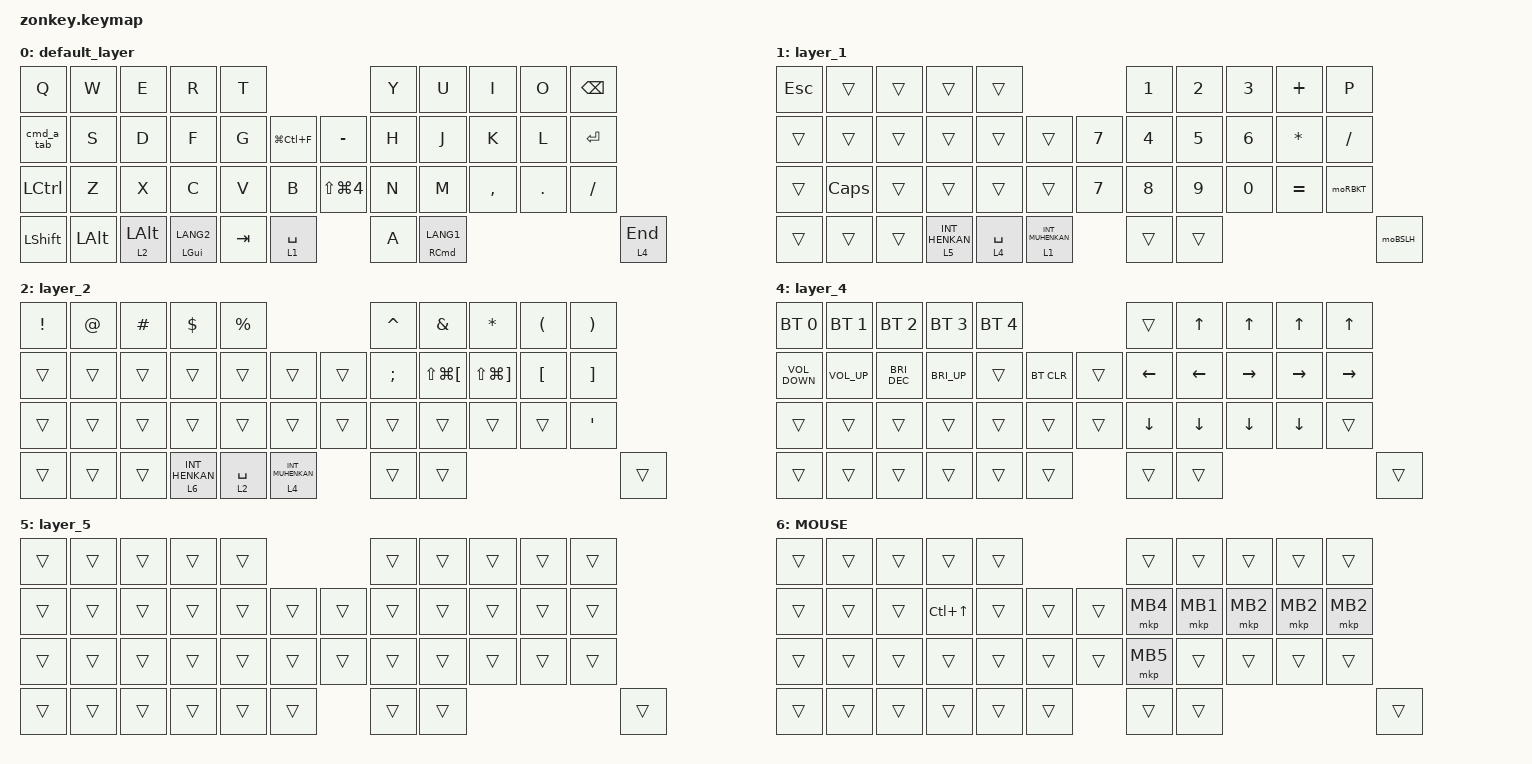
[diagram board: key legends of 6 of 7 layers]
#include <behaviors.dtsi>
#include <dt-bindings/zmk/bt.h>
#include <dt-bindings/zmk/keys.h>
#include <dt-bindings/zmk/pointing.h>

#define ZMK_POINTING_DEFAULT_SCRL_VAL 100
#define JIS 1
#define BT 4
#define MOUSE 6

&mt {
    flavor = "balanced";
    quick-tap-ms = <0>;
};

/ {
    behaviors {
        cmd_a_tab: cmd_a_tab {
            compatible = "zmk,behavior-mod-morph";
            #binding-cells = <0>;

            /* Tab 単体を送る */

            bindings = <&kp A>, <&kp TAB>;

            /* Left GUI が押されている時だけモーフ */

            mods = <(MOD_LGUI)>;

            /* その Left GUI をホストへ“保持”して渡す！ */

            keep-mods = <(MOD_LGUI)>;
        };

        cmd_sel_all: cmd_sel_all {
            compatible = "zmk,behavior-macro";
            #binding-cells = <0>;
            bindings = <&kp LEFT_GUI &kp A>;   /* ⌘ と A を同時送信 */
            label = "CMD_SELECT_ALL";
        };
    };

    macros {
        to_layer_0: to_layer_0 {
            compatible = "zmk,behavior-macro-one-param";
            #binding-cells = <1>;
            bindings = <&to 0 &macro_param_1to1 &kp MACRO_PLACEHOLDER>;
            label = "TO_LAYER_0";
        };

        screenshot_select: screenshot_select {
            compatible = "zmk,behavior-macro";
            #binding-cells = <0>;
            bindings = <&kp LEFT_GUI &kp LEFT_SHIFT &kp KP_NUMBER_4>;
            label = "SCREENSHOT_SELECT";
        };
    };

    behaviors {
        lt_to_layer_0: lt_to_layer_0 {
            compatible = "zmk,behavior-hold-tap";
            label = "LAYER_TAP_TO_0";
            bindings = <&mo>, <&to_layer_0>;

            #binding-cells = <2>;
            tapping-term-ms = <10>;
        };

        toJIS: toJIS {
            compatible = "zmk,behavior-hold-tap";
            label = "toJIS";
            #binding-cells = <2>;
            tapping-term-ms = <200>;
            quick-tap-ms = <0>;
            bindings = <&tog>, <&kp>;
        };

        mo2: mo2 {
            compatible = "zmk,behavior-mod-morph";
            #binding-cells = <0>;
            bindings = <&kp N2>, <&kp DQT>;

            mods = <(MOD_LSFT|MOD_RSFT)>;
        };

        mo6: mo6 {
            compatible = "zmk,behavior-mod-morph";
            #binding-cells = <0>;
            bindings = <&kp N6>, <&kp AMPS>;

            mods = <(MOD_LSFT|MOD_RSFT)>;
        };

        mo7: mo7 {
            compatible = "zmk,behavior-mod-morph";
            #binding-cells = <0>;
            bindings = <&kp N7>, <&kp APOS>;

            mods = <(MOD_LSFT|MOD_RSFT)>;
        };

        mo8: mo8 {
            compatible = "zmk,behavior-mod-morph";
            #binding-cells = <0>;
            bindings = <&kp N8>, <&kp LPAR>;

            mods = <(MOD_LSFT|MOD_RSFT)>;
        };

        mo9: mo9 {
            compatible = "zmk,behavior-mod-morph";
            #binding-cells = <0>;
            bindings = <&kp N9>, <&kp RPAR>;

            mods = <(MOD_LSFT|MOD_RSFT)>;
        };

        moMINUS: moMINUS {
            compatible = "zmk,behavior-mod-morph";
            #binding-cells = <0>;
            bindings = <&kp MINUS>, <&kp EQUAL>;

            mods = <(MOD_LSFT|MOD_RSFT)>;
        };

        moCARET: moCARET {
            compatible = "zmk,behavior-mod-morph";
            #binding-cells = <0>;
            bindings = <&kp CARET>, <&kp TILDE>;

            mods = <(MOD_LSFT|MOD_RSFT)>;
        };

        moINT3: moINT3 {
            compatible = "zmk,behavior-mod-morph";
            #binding-cells = <0>;
            bindings = <&kp INT3>, <&kp PIPE>;

            mods = <(MOD_LSFT|MOD_RSFT)>;
        };

        moAT: moAT {
            compatible = "zmk,behavior-mod-morph";
            #binding-cells = <0>;
            bindings = <&kp AT>, <&kp GRAVE>;

            mods = <(MOD_LSFT|MOD_RSFT)>;
        };

        moLBKT: moLBKT {
            compatible = "zmk,behavior-mod-morph";
            #binding-cells = <0>;
            bindings = <&kp LBKT>, <&kp LS(LBRC)>;

            mods = <(MOD_LSFT|MOD_RSFT)>;
        };

        moRBKT: moRBKT {
            compatible = "zmk,behavior-mod-morph";
            #binding-cells = <0>;
            bindings = <&kp RBKT>, <&kp LS(RBRC)>;

            mods = <(MOD_LSFT|MOD_RSFT)>;
        };

        moSEMI: moSEMI {
            compatible = "zmk,behavior-mod-morph";
            #binding-cells = <0>;
            bindings = <&kp SEMI>, <&kp PLUS>;

            mods = <(MOD_LSFT|MOD_RSFT)>;
        };

        moCOLON: moCOLON {
            compatible = "zmk,behavior-mod-morph";
            #binding-cells = <0>;
            bindings = <&kp COLON>, <&kp ASTRK>;

            mods = <(MOD_LSFT|MOD_RSFT)>;
        };

        moBSLH: moBSLH {
            compatible = "zmk,behavior-mod-morph";
            #binding-cells = <0>;
            bindings = <&kp BSLH>, <&kp UNDER>;

            mods = <(MOD_LSFT|MOD_RSFT)>;
        };

        /* New behaviour: Cmd+A → Cmd+Tab, A 単押し → a */

        a_cmd_tab: a_cmd_tab {
            compatible = "zmk,behavior-mod-morph";
            #binding-cells = <0>;
            bindings = <&kp A>, <&kp TAB>;

            mods = <(MOD_LGUI)>;
        };

        scroll_down_up: behavior_sensor_rotate_mouse_wheel_down_up {
            compatible = "zmk,behavior-sensor-rotate";
            #sensor-binding-cells = <0>;
            bindings = <&msc SCRL_DOWN>, <&msc SCRL_UP>;

            tap-ms = <20>;
        };
    };

    keymap {
        compatible = "zmk,keymap";

        default_layer {
            bindings = <
&kp Q             &kp W         &kp E           &kp R               &kp T                                           &kp Y  &kp U                    &kp I      &kp O       &kp BACKSPACE
&cmd_a_tab        &kp S         &kp D           &kp F               &kp G    &kp LG(LC(F))    &kp MINUS             &kp H  &kp J                    &kp K      &kp L       &kp ENTER
&kp LEFT_CONTROL  &kp Z         &kp X           &kp C               &kp V    &kp B            &kp LS(LG(NUMBER_4))  &kp N  &kp M                    &kp COMMA  &kp PERIOD  &kp SLASH
&kp LEFT_SHIFT    &kp LEFT_ALT  &lt 2 LEFT_ALT  &mt LEFT_GUI LANG2  &kp TAB  &lt 1 SPACE                            &kp A  &mt RIGHT_COMMAND LANG1                                        &lt 4 END
            >;

            sensor-bindings =
                <&scroll_down_up>,
                <&inc_dec_kp C_VOL_DN C_VOL_UP>;
        };

        layer_1 {
            bindings = <
&kp ESCAPE  &trans    &trans  &trans            &trans                                           &kp NUMBER_1  &kp NUMBER_2  &kp NUMBER_3  &kp PLUS      &kp P
&trans      &trans    &trans  &trans            &trans       &trans                &kp NUMBER_7  &kp NUMBER_4  &kp NUMBER_5  &kp NUMBER_6  &kp ASTERISK  &kp SLASH
&trans      &kp CAPS  &trans  &trans            &trans       &trans                &kp NUMBER_7  &kp NUMBER_8  &kp NUMBER_9  &kp NUMBER_0  &kp EQUAL     &moRBKT
&trans      &trans    &trans  &lt 5 INT_HENKAN  &lt 4 SPACE  &lt 1 INT_MUHENKAN                  &trans        &trans                                               &moBSLH
            >;

            sensor-bindings = <&scroll_down_up>;
        };

        layer_2 {
            bindings = <
&kp EXCLAMATION  &kp AT_SIGN  &kp HASH  &kp DOLLAR        &kp PERCENT                                &kp CARET      &kp AMPERSAND             &kp ASTERISK               &kp LEFT_PARENTHESIS  &kp RIGHT_PARENTHESIS
&trans           &trans       &trans    &trans            &trans       &trans                &trans  &kp SEMICOLON  &kp LS(LG(LEFT_BRACKET))  &kp LS(LG(RIGHT_BRACKET))  &kp LEFT_BRACKET      &kp RIGHT_BRACKET
&trans           &trans       &trans    &trans            &trans       &trans                &trans  &trans         &trans                    &trans                     &trans                &kp SINGLE_QUOTE
&trans           &trans       &trans    &lt 6 INT_HENKAN  &lt 2 SPACE  &lt 4 INT_MUHENKAN            &trans         &trans                                                                                            &trans
            >;

            sensor-bindings = <&scroll_down_up>;
        };

        layer_3 {
            bindings = <
&kp F1   &kp F2   &kp F3            &kp F4       &kp F5                                &kp F6  &kp F7  &kp F8  &kp F9  &kp F10
&kp F11  &kp F12  &trans            &trans       &trans              &trans    &trans  &trans  &trans  &trans  &trans  &trans
&trans   &trans   &trans            &trans       &trans              &trans    &trans  &trans  &trans  &trans  &trans  &trans
&trans   &trans   &lt 3 INT_HENKAN  &lt 6 SPACE  &lt 5 INT_MUHENKAN  &trans            &trans  &trans
            >;

            sensor-bindings = <&scroll_down_up>;
        };

        layer_4 {
            bindings = <
&bt BT_SEL 0       &bt BT_SEL 1     &bt BT_SEL 2   &bt BT_SEL 3  &bt BT_SEL 4                        &trans          &kp UP_ARROW    &kp UP_ARROW     &kp UP_ARROW     &kp UP_ARROW
&kp C_VOLUME_DOWN  &kp C_VOLUME_UP  &kp C_BRI_DEC  &kp C_BRI_UP  &trans        &bt BT_CLR    &trans  &kp LEFT_ARROW  &kp LEFT_ARROW  &kp RIGHT_ARROW  &kp RIGHT_ARROW  &kp RIGHT_ARROW
&trans             &trans           &trans         &trans        &trans        &trans        &trans  &kp DOWN_ARROW  &kp DOWN_ARROW  &kp DOWN_ARROW   &kp DOWN_ARROW   &trans
&trans             &trans           &trans         &trans        &trans        &trans                &trans          &trans                                                             &trans
            >;

            sensor-bindings = <&scroll_down_up>;
        };

        layer_5 {
            bindings = <
&trans  &trans  &trans  &trans  &trans                    &trans  &trans  &trans  &trans  &trans
&trans  &trans  &trans  &trans  &trans  &trans    &trans  &trans  &trans  &trans  &trans  &trans
&trans  &trans  &trans  &trans  &trans  &trans    &trans  &trans  &trans  &trans  &trans  &trans
&trans  &trans  &trans  &trans  &trans  &trans            &trans  &trans                          &trans
            >;

            sensor-bindings = <&scroll_down_up>;
        };

        MOUSE {
            bindings = <
&trans  &trans  &trans  &trans            &trans                    &trans    &trans    &trans    &trans    &trans
&trans  &trans  &trans  &kp LC(UP_ARROW)  &trans  &trans    &trans  &mkp MB4  &mkp MB1  &mkp MB2  &mkp MB2  &mkp MB2
&trans  &trans  &trans  &trans            &trans  &trans    &trans  &mkp MB5  &trans    &trans    &trans    &trans
&trans  &trans  &trans  &trans            &trans  &trans            &trans    &trans                                  &trans
            >;

            sensor-bindings = <&scroll_down_up>;
        };
    };
};
